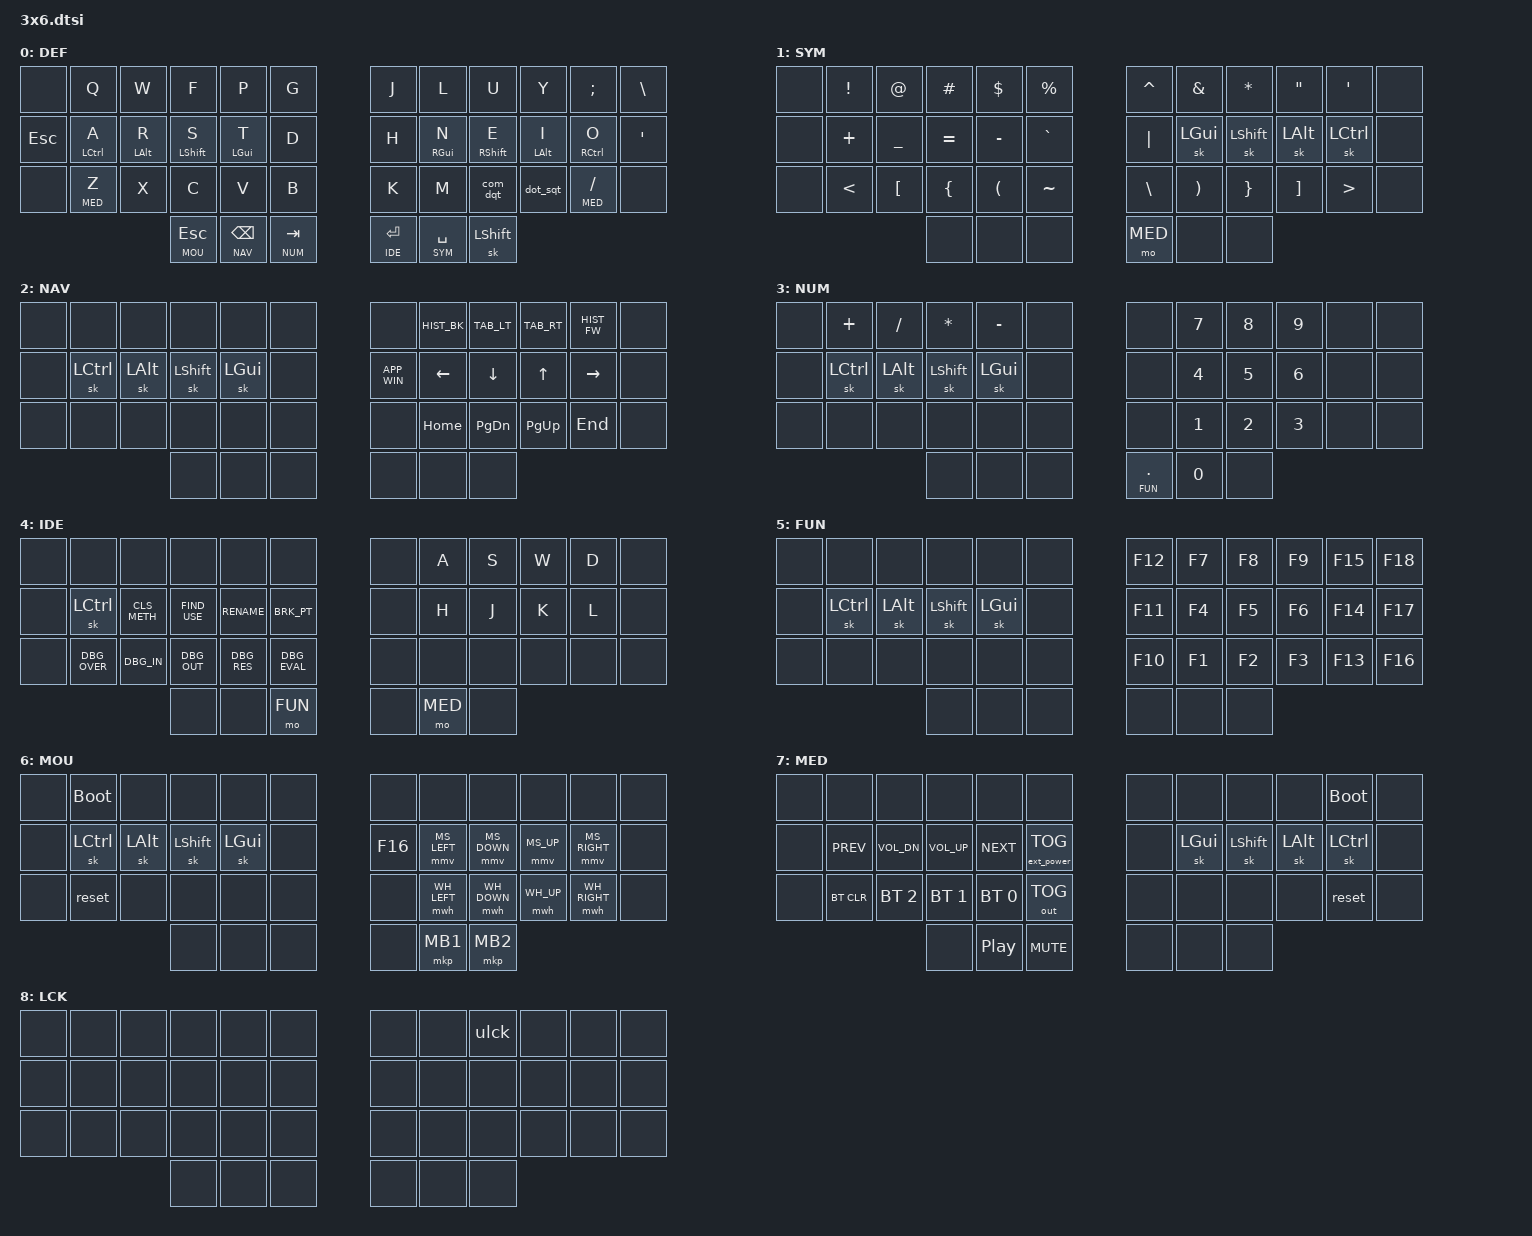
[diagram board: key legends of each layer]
/*
 * Copyright (c) 2020 The ZMK Contributors
 *
 * SPDX-License-Identifier: MIT
 */

#include <behaviors.dtsi>
#include <dt-bindings/zmk/keys.h>
#include <dt-bindings/zmk/bt.h>
#include <dt-bindings/zmk/ext_power.h>
#include <dt-bindings/zmk/mouse.h>
#include <dt-bindings/zmk/outputs.h>

// Layer aliases
#define DEF 0
#define SYM 1
#define NAV 2
#define NUM 3
#define IDE 4
#define FUN 5
#define MOU 6
#define MED 7
#define LCK 8

// Key position groups
#define KEYS_L 0 1 2 3 4 5 12 13 14 15 16 17 24 25 26 27 28 29
#define KEYS_R 6 7 8 9 10 18 19 20 21 22 23 30 31 32 33 34 35
#define THUMBS 36 37 38 39 40 41

// Define shortcuts
#define VIMAC    LG(LS(LA(LC(F))))
#define EMOJ     LG(LC(SPACE))
#define ALFR     LG(SPACE)
#define CTXS     LA(TAB)
#define HIST_BK  LG(LBKT)
#define HIST_FW  LG(RBKT)
#define TAB_LT   LS(LG(LBKT))
#define TAB_RT   LS(LG(RBKT))
#define APP_WIN  LG(GRAVE)
#define HYPER    LG(LS(LA(LCTRL)))
#define MEH      LS(LA(LCTRL))

// IJ shortcuts
#define CLS_METH LG(F12)
#define FIND_USE LA(F7)
#define RENAME   LS(F6)
#define BRK_PT   LG(F8)
#define DBG_OVER F8
#define DBG_IN   F7
#define DBG_OUT  LS(F8)
#define DBG_RES  LA(LG(R))
#define DBG_EVAL LA(F8)

// Mouse
#define U_MOUSE_MOVE_MAX 1250
#define U_MOUSE_MOVE_EXPONENT 1
#define U_MOUSE_MOVE_TIME 1500
#define U_MOUSE_MOVE_DELAY 0
#define U_MOUSE_SCROLL_MAX 100
#define U_MOUSE_SCROLL_EXPONENT 1
#define U_MOUSE_SCROLL_TIME 5000
#define U_MOUSE_SCROLL_DELAY 0
#define MS_UP MOVE_VERT(-U_MOUSE_MOVE_MAX)
#define MS_DOWN MOVE_VERT(U_MOUSE_MOVE_MAX)
#define MS_LEFT MOVE_HOR(-U_MOUSE_MOVE_MAX)
#define MS_RIGHT MOVE_HOR(U_MOUSE_MOVE_MAX)
#define WH_UP SCROLL_VERT(U_MOUSE_SCROLL_MAX)
#define WH_DOWN SCROLL_VERT(-U_MOUSE_SCROLL_MAX)
#define WH_LEFT SCROLL_HOR(-U_MOUSE_SCROLL_MAX)
#define WH_RIGHT SCROLL_HOR(U_MOUSE_SCROLL_MAX)

#define TAPPING_TERM_MS 280
#define QUICK_TAP_MS 175
#define GLOBAL_QUICK_TAP_MS 150

&mt {
    flavor = "tap-preferred";
    tapping-term-ms = <220>;
    quick-tap-ms = <220>;
    hold-trigger-key-positions = <0>;
};

&lt {
    flavor = "balanced";
    tapping-term-ms = <200>;
    quick-tap-ms = <QUICK_TAP_MS>;
};

&sk {
    release-after-ms = <5000>;
};

&sl {
    ignore-modifiers;
    release-after-ms = <5000>;
};

&caps_word {
    continue-list = <UNDERSCORE MINUS BSPC DEL N1 N2 N3 N4 N5 N6 N7 N8 N9 N0>;
};

&mmv {
  acceleration-exponent = <U_MOUSE_MOVE_EXPONENT>;
  time-to-max-speed-ms = <U_MOUSE_MOVE_TIME>;
  delay-ms = <U_MOUSE_MOVE_DELAY>;
};

&mwh {
  acceleration-exponent = <U_MOUSE_SCROLL_EXPONENT>;
  time-to-max-speed-ms = <U_MOUSE_SCROLL_TIME>;
  delay-ms = <U_MOUSE_SCROLL_DELAY>;
};

/ {
    combos {
        #include "combos-3x6.dtsi"
    };

    /* conditional_layers {
        compatible = "zmk,conditional-layers";
        tri_layer {
            if-layers = <NAV SYM>;
            then-layer = <NUM>;
        };
    }; */

    behaviors {
        hml: home_mods_l {
            compatible = "zmk,behavior-hold-tap";
            label = "HOME_MT_L";
            flavor = "balanced";
            tapping-term-ms = <280>;
            quick-tap-ms = <QUICK_TAP_MS>;
            global-quick-tap-ms = <GLOBAL_QUICK_TAP_MS>;
            hold-trigger-key-positions = <KEYS_R THUMBS>;
            hold-trigger-on-release;
            #binding-cells = <2>;
            bindings = <&kp>, <&kp>;
        };

        hmr: home_mods_r {
            compatible = "zmk,behavior-hold-tap";
            label = "HOME_MT_R";
            flavor = "balanced";
            tapping-term-ms = <280>;
            quick-tap-ms = <QUICK_TAP_MS>;
            global-quick-tap-ms = <GLOBAL_QUICK_TAP_MS>;
            hold-trigger-key-positions = <KEYS_L THUMBS>;
            hold-trigger-on-release;
            #binding-cells = <2>;
            bindings = <&kp>, <&kp>;
        };

        ulck: tap_dance_0 {
            compatible = "zmk,behavior-tap-dance";
            label = "td_unlock";
            #binding-cells = <0>;
            tapping-term-ms = <150>;
            bindings = <&none>, <&to DEF>;
        };

        com_dqt: comma_dqt {
            compatible = "zmk,behavior-mod-morph";
            label = "COMMA_DQT";
            #binding-cells = <0>;
            bindings = <&kp COMMA>, <&kp DQT>;
            mods = <(MOD_LSFT|MOD_RSFT)>;
        };

        dot_sqt: dot_sqt {
            compatible = "zmk,behavior-mod-morph";
            label = "DOT_SQT";
            #binding-cells = <0>;
            bindings = <&kp DOT>, <&kp SQT>;
            mods = <(MOD_LSFT|MOD_RSFT)>;
        };

        bsp_del: bsp_del {
            compatible = "zmk,behavior-mod-morph";
            label = "BSP_DEL";
            #binding-cells = <0>;
            bindings = <&kp BSPC>, <&kp DEL>;
            mods = <(MOD_LSFT|MOD_RSFT)>;
        };

        lt2: lt2 {
            compatible = "zmk,behavior-hold-tap";
            label = "lt2";
            #binding-cells = <2>;
            bindings = <&mo>, <&bsp_del>;
            flavor = "balanced";
            tapping-term-ms = <200>;
            quick-tap-ms = <QUICK_TAP_MS>;
        };
    };

    keymap {
        compatible = "zmk,keymap";

        layer_default {
            label = "DEF";
            bindings = <
// ╭─────────────┬─────────────┬─────────────┬─────────────┬─────────────┬─────────────╮   ╭─────────────┬─────────────┬─────────────┬─────────────┬─────────────┬─────────────╮
     &none         &kp Q         &kp W         &kp F         &kp P         &kp G             &kp J         &kp L         &kp U         &kp Y         &kp SEMI      &kp BSLH
// ├─────────────┼─────────────┼─────────────┼─────────────┼─────────────┼─────────────┤   ├─────────────┼─────────────┼─────────────┼─────────────┼─────────────┼─────────────┤
     &kp ESC       &hml LCTRL A  &hml LALT R   &hml LSHFT S  &hml LGUI T   &kp D             &kp H         &hmr RGUI N   &hmr RSHFT E  &hmr LALT I   &hmr RCTRL O  &kp SQT
// ├─────────────┼─────────────┼─────────────┼─────────────┼─────────────┼─────────────┤   ├─────────────┼─────────────┼─────────────┼─────────────┼─────────────┼─────────────┤
     &none         &lt MED Z     &kp X         &kp C         &kp V         &kp B             &kp K         &kp M         &com_dqt      &dot_sqt      &lt MED FSLH  &none
// ╰─────────────┴─────────────┴─────────────┼─────────────┼─────────────┼─────────────┤   ├─────────────┼─────────────┼─────────────┼─────────────┴─────────────┴─────────────╯
                                               &lt MOU ESC   &lt2 NAV BSPC &lt NUM TAB       &lt IDE RET   &lt SYM SPACE &sk LSHFT
//                                           ╰─────────────┴─────────────┴─────────────╯   ╰─────────────┴─────────────┴─────────────╯
            >;
        };

        layer_symbols {
            label = "SYM";
            bindings = <
// ╭─────────────┬─────────────┬─────────────┬─────────────┬─────────────┬─────────────╮   ╭─────────────┬─────────────┬─────────────┬─────────────┬─────────────┬─────────────╮
     &none         &kp EXCL      &kp AT        &kp HASH      &kp DLLR      &kp PRCNT         &kp CARET     &kp AMPS      &kp STAR      &kp DQT       &kp SQT       &none
// ├─────────────┼─────────────┼─────────────┼─────────────┼─────────────┼─────────────┤   ├─────────────┼─────────────┼─────────────┼─────────────┼─────────────┼─────────────┤
     &none         &kp PLUS      &kp UNDER     &kp EQUAL     &kp MINUS     &kp GRAVE         &kp PIPE      &sk LGUI      &sk LSHFT     &sk LALT      &sk LCTRL     &none
// ├─────────────┼─────────────┼─────────────┼─────────────┼─────────────┼─────────────┤   ├─────────────┼─────────────┼─────────────┼─────────────┼─────────────┼─────────────┤
     &none         &kp LT        &kp LBKT      &kp LBRC      &kp LPAR      &kp TILDE         &kp BSLH      &kp RPAR      &kp RBRC      &kp RBKT      &kp GT        &none
// ╰─────────────┴─────────────┴─────────────┼─────────────┼─────────────┼─────────────┤   ├─────────────┼─────────────┼─────────────┼─────────────┴─────────────┴─────────────╯
                                               &none         &none         &none             &mo MED       &none         &none
//                                           ╰─────────────┴─────────────┴─────────────╯   ╰─────────────┴─────────────┴─────────────╯
            >;
        };

        layer_nav {
            label = "NAV";            
            bindings = <
// ╭─────────────┬─────────────┬─────────────┬─────────────┬─────────────┬─────────────╮   ╭─────────────┬─────────────┬─────────────┬─────────────┬─────────────┬─────────────╮
     &none         &none         &none         &none         &none         &none             &none         &kp HIST_BK   &kp TAB_LT    &kp TAB_RT    &kp HIST_FW   &none
// ├─────────────┼─────────────┼─────────────┼─────────────┼─────────────┼─────────────┤   ├─────────────┼─────────────┼─────────────┼─────────────┼─────────────┼─────────────┤
     &none         &sk LCTRL     &sk LALT      &sk LSHFT     &sk LGUI      &none             &kp APP_WIN   &kp LEFT      &kp DOWN      &kp UP        &kp RIGHT     &none
// ├─────────────┼─────────────┼─────────────┼─────────────┼─────────────┼─────────────┤   ├─────────────┼─────────────┼─────────────┼─────────────┼─────────────┼─────────────┤
     &none         &none         &none         &none         &none         &none             &none         &kp HOME      &kp PG_DN     &kp PG_UP     &kp END       &none
// ╰─────────────┴─────────────┴─────────────┼─────────────┼─────────────┼─────────────┤   ├─────────────┼─────────────┼─────────────┼─────────────┴─────────────┴─────────────╯
                                               &none         &none         &none             &none         &none         &none
//                                           ╰─────────────┴─────────────┴─────────────╯   ╰─────────────┴─────────────┴─────────────╯
            >;
        };

        layer_num {
            label = "NUM";
            bindings = <
// ╭─────────────┬─────────────┬─────────────┬─────────────┬─────────────┬─────────────╮   ╭─────────────┬─────────────┬─────────────┬─────────────┬─────────────┬─────────────╮
     &none         &kp PLUS      &kp FSLH      &kp STAR      &kp MINUS     &none             &none         &kp N7        &kp N8        &kp N9        &none         &none
// ├─────────────┼─────────────┼─────────────┼─────────────┼─────────────┼─────────────┤   ├─────────────┼─────────────┼─────────────┼─────────────┼─────────────┼─────────────┤
     &none         &sk LCTRL     &sk LALT      &sk LSHFT     &sk LGUI      &none             &none         &kp N4        &kp N5        &kp N6        &none         &none
// ├─────────────┼─────────────┼─────────────┼─────────────┼─────────────┼─────────────┤   ├─────────────┼─────────────┼─────────────┼─────────────┼─────────────┼─────────────┤
     &none         &none         &none         &none         &none         &none             &none         &kp N1        &kp N2        &kp N3        &none         &none
// ╰─────────────┴─────────────┴─────────────┼─────────────┼─────────────┼─────────────┤   ├─────────────┼─────────────┼─────────────┼─────────────┴─────────────┴─────────────╯
                                               &none         &none         &none             &lt FUN DOT   &kp N0        &none
//                                           ╰─────────────┴─────────────┴─────────────╯   ╰─────────────┴─────────────┴─────────────╯
            >;
        };

        layer_ide {
            label = "IDE";
            bindings = <
// ╭─────────────┬─────────────┬─────────────┬─────────────┬─────────────┬─────────────╮   ╭─────────────┬─────────────┬─────────────┬─────────────┬─────────────┬─────────────╮
     &none         &none         &none         &none         &none         &none             &none         &kp A         &kp S         &kp W         &kp D         &none
// ├─────────────┼─────────────┼─────────────┼─────────────┼─────────────┼─────────────┤   ├─────────────┼─────────────┼─────────────┼─────────────┼─────────────┼─────────────┤
     &none         &sk LCTRL     &kp CLS_METH  &kp FIND_USE  &kp RENAME    &kp BRK_PT        &none         &kp H         &kp J         &kp K         &kp L         &none
// ├─────────────┼─────────────┼─────────────┼─────────────┼─────────────┼─────────────┤   ├─────────────┼─────────────┼─────────────┼─────────────┼─────────────┼─────────────┤
     &none         &kp DBG_OVER  &kp DBG_IN    &kp DBG_OUT   &kp DBG_RES   &kp DBG_EVAL      &none         &none         &none         &none         &none         &none
// ╰─────────────┴─────────────┴─────────────┼─────────────┼─────────────┼─────────────┤   ├─────────────┼─────────────┼─────────────┼─────────────┴─────────────┴─────────────╯
                                               &none         &none         &mo FUN           &none         &mo MED       &none
//                                           ╰─────────────┴─────────────┴─────────────╯   ╰─────────────┴─────────────┴─────────────╯
            >;
        };

        layer_fun {
            label = "FUN";
            bindings = <
// ╭─────────────┬─────────────┬─────────────┬─────────────┬─────────────┬─────────────╮   ╭─────────────┬─────────────┬─────────────┬─────────────┬─────────────┬─────────────╮
     &none         &none         &none         &none         &none         &none             &kp F12       &kp F7        &kp F8        &kp F9        &kp F15       &kp F18
// ├─────────────┼─────────────┼─────────────┼─────────────┼─────────────┼─────────────┤   ├─────────────┼─────────────┼─────────────┼─────────────┼─────────────┼─────────────┤
     &none         &sk LCTRL     &sk LALT      &sk LSHFT     &sk LGUI      &none             &kp F11       &kp F4        &kp F5        &kp F6        &kp F14       &kp F17
// ├─────────────┼─────────────┼─────────────┼─────────────┼─────────────┼─────────────┤   ├─────────────┼─────────────┼─────────────┼─────────────┼─────────────┼─────────────┤
     &none         &none         &none         &none         &none         &none             &kp F10       &kp F1        &kp F2        &kp F3        &kp F13       &kp F16
// ╰─────────────┴─────────────┴─────────────┼─────────────┼─────────────┼─────────────┤   ├─────────────┼─────────────┼─────────────┼─────────────┴─────────────┴─────────────╯
                                               &none         &none         &none             &none         &none         &none
//                                           ╰─────────────┴─────────────┴─────────────╯   ╰─────────────┴─────────────┴─────────────╯
            >;
        };

        layer_mouse {
            label = "MOU";
            bindings = <
// ╭─────────────┬─────────────┬─────────────┬─────────────┬─────────────┬─────────────╮   ╭─────────────┬─────────────┬─────────────┬─────────────┬─────────────┬─────────────╮
     &none         &bootloader   &none         &none         &none         &none             &none         &none         &none         &none         &none         &none
// ├─────────────┼─────────────┼─────────────┼─────────────┼─────────────┼─────────────┤   ├─────────────┼─────────────┼─────────────┼─────────────┼─────────────┼─────────────┤
     &none         &sk LCTRL     &sk LALT      &sk LSHFT     &sk LGUI      &none             &kp F16       &mmv MS_LEFT  &mmv MS_DOWN  &mmv MS_UP    &mmv MS_RIGHT &none
// ├─────────────┼─────────────┼─────────────┼─────────────┼─────────────┼─────────────┤   ├─────────────┼─────────────┼─────────────┼─────────────┼─────────────┼─────────────┤
     &none         &reset        &none         &none         &none         &none             &none         &mwh WH_LEFT  &mwh WH_DOWN  &mwh WH_UP    &mwh WH_RIGHT &none
// ╰─────────────┴─────────────┴─────────────┼─────────────┼─────────────┼─────────────┤   ├─────────────┼─────────────┼─────────────┼─────────────┴─────────────┴─────────────╯
                                               &none         &none         &none             &none         &mkp MB1      &mkp MB2
//                                           ╰─────────────┴─────────────┴─────────────╯   ╰─────────────┴─────────────┴─────────────╯
            >;        
        };

     layer_media {
            label = "MED";
            bindings = <
// ╭─────────────┬─────────────┬─────────────┬─────────────┬─────────────┬─────────────╮   ╭─────────────┬─────────────┬─────────────┬─────────────┬─────────────┬─────────────╮
     &none         &none         &none         &none         &none         &none             &none         &none         &none         &none         &bootloader   &none
// ├─────────────┼─────────────┼─────────────┼─────────────┼─────────────┼─────────────┤   ├─────────────┼─────────────┼─────────────┼─────────────┼─────────────┼─────────────┤
     &none         &kp C_PREV    &kp C_VOL_DN  &kp C_VOL_UP  &kp C_NEXT    &ext_power EP_TOG &none         &sk LGUI      &sk LSHFT     &sk LALT      &sk LCTRL     &none
// ├─────────────┼─────────────┼─────────────┼─────────────┼─────────────┼─────────────┤   ├─────────────┼─────────────┼─────────────┼─────────────┼─────────────┼─────────────┤
     &none         &bt BT_CLR    &bt BT_SEL 2  &bt BT_SEL 1  &bt BT_SEL 0  &out OUT_TOG      &none         &none         &none         &none         &reset        &none
// ╰─────────────┴─────────────┴─────────────┼─────────────┼─────────────┼─────────────┤   ├─────────────┼─────────────┼─────────────┼─────────────┴─────────────┴─────────────╯
                                               &none         &kp C_PP      &kp C_MUTE        &none         &none         &none
//                                           ╰─────────────┴─────────────┴─────────────╯   ╰─────────────┴─────────────┴─────────────╯
            >;        
        };

        layer_lockout {
            label = "LCK";
            bindings = <
// ╭─────────────┬─────────────┬─────────────┬─────────────┬─────────────┬─────────────╮   ╭─────────────┬─────────────┬─────────────┬─────────────┬─────────────┬─────────────╮
     &none         &none         &none         &none         &none         &none             &none         &none         &ulck         &none         &none         &none
// ├─────────────┼─────────────┼─────────────┼─────────────┼─────────────┼─────────────┤   ├─────────────┼─────────────┼─────────────┼─────────────┼─────────────┼─────────────┤
     &none         &none         &none         &none         &none         &none             &none         &none         &none         &none         &none         &none
// ├─────────────┼─────────────┼─────────────┼─────────────┼─────────────┼─────────────┤   ├─────────────┼─────────────┼─────────────┼─────────────┼─────────────┼─────────────┤
     &none         &none         &none         &none         &none         &none             &none         &none         &none         &none         &none         &none
// ╰─────────────┴─────────────┴─────────────┼─────────────┼─────────────┼─────────────┤   ├─────────────┼─────────────┼─────────────┼─────────────┴─────────────┴─────────────╯
                                               &none         &none         &none             &none         &none         &none
//                                           ╰─────────────┴─────────────┴─────────────╯   ╰─────────────┴─────────────┴─────────────╯
            >;        
        };
    };
};
